# F28x7x_cpu_sys_regs register map
Vendor: Texas Instruments
Peripheral module from a debugger description file (folder C2000).
Address unit: 16 bits
Registers are 32-bit, read-write, no defined reset value unless marked. A register's access mark holds for its fields unless they carry their own. Offsets are as the file gives them; lines under a group give offsets from that group; [hi:lo] are bit positions; {n}, {i} and the like mark numbered series; 'fields as' and 'values as' point back to an identical list; <NAME> marks a mode.

## CPU_SYS_REGS
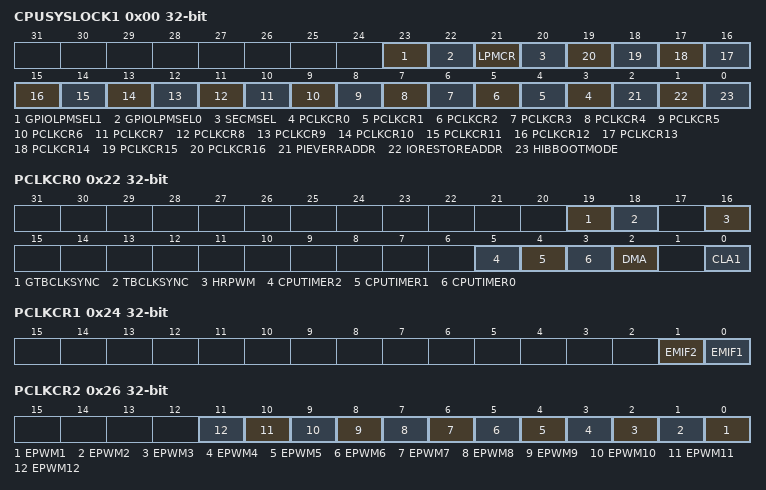
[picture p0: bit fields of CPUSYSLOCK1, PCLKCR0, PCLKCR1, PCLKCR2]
0x00 CPUSYSLOCK1 — Lock bit for CPUSYS registers
  [23] GPIOLPMSEL1 — Lock bit for GPIOLPMSEL1 Register
  [22] GPIOLPMSEL0 — Lock bit for GPIOLPMSEL0 Register
  [21] LPMCR — Lock bit for LPMCR Register
  [20] SECMSEL — Lock bit for SECMSEL Register
  [n+3] PCLKCR{n} (n=0..16) — Lock bit for PCLKCR{n} Register
  [2] PIEVERRADDR — Lock bit for PIEVERRADDR Register
  [1] IORESTOREADDR — Lock bit for IORESTOREADDR Register
  [0] HIBBOOTMODE — Lock bit for HIBBOOTMODE register
0x06 HIBBOOTMODE
  [31:0] BMODE — HIB Boot Mode
0x08 IORESTOREADDR — IORestore() routine Address Register
  [21:0] ADDR — restoreIO() routine address
0x0A PIEVERRADDR — PIE Vector Fetch Error Address register
  [21:0] ADDR — PIE Vector Fetch Error Handler Routine Address
0x22 PCLKCR0 — Peripheral Clock Gating Registers
  [19] GTBCLKSYNC — EPWM Time Base Clock Global sync
  [18] TBCLKSYNC — EPWM Time Base Clock sync
  [16] HRPWM — HRPWM Clock Enable Bit
  [5] CPUTIMER2 — CPUTIMER2 Clock Enable bit
  [4] CPUTIMER1 — CPUTIMER1 Clock Enable bit
  [3] CPUTIMER0 — CPUTIMER0 Clock Enable bit
  [2] DMA — DMA Clock Enable bit
  [0] CLA1 — CLA1 Clock Enable Bit
0x24 PCLKCR1 — Peripheral Clock Gating Registers
  [1] EMIF2 — EMIF2 Clock Enable bit
  [0] EMIF1 — EMIF1 Clock Enable bit
0x26 PCLKCR2 — Peripheral Clock Gating Registers
  [n-1] EPWM{n} (n=1..12) — EPWM{n} Clock Enable bit
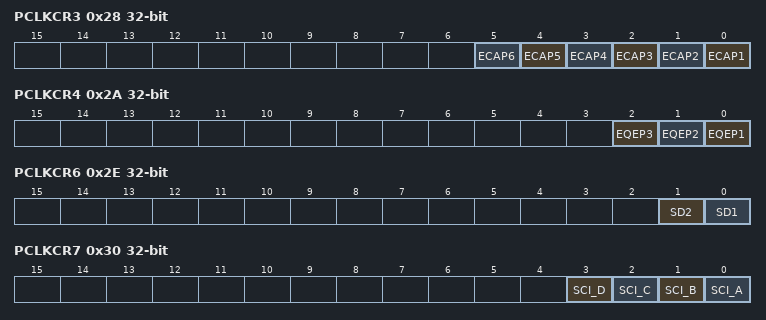
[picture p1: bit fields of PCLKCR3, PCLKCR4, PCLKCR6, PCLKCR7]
0x28 PCLKCR3 — Peripheral Clock Gating Registers
  [n-1] ECAP{n} (n=1..6) — ECAP{n} Clock Enable bit
0x2A PCLKCR4 — Peripheral Clock Gating Registers
  [2] EQEP3 — EQEP3 Clock Enable bit
  [1] EQEP2 — EQEP2 Clock Enable bit
  [0] EQEP1 — EQEP1 Clock Enable bit
0x2C PCLKCR5 access not given — Peripheral Clock Gating Registers
0x2E PCLKCR6 — Peripheral Clock Gating Registers
  [1] SD2 — SD2 Clock Enable bit
  [0] SD1 — SD1 Clock Enable bit
0x30 PCLKCR7 — Peripheral Clock Gating Registers
  [3] SCI_D — SCI_D Clock Enable bit
  [2] SCI_C — SCI_C Clock Enable bit
  [1] SCI_B — SCI_B Clock Enable bit
  [0] SCI_A — SCI_A Clock Enable bit
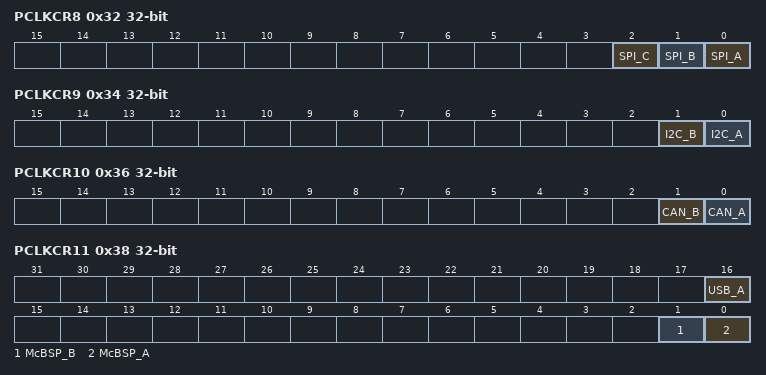
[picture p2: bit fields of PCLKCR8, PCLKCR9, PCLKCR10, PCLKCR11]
0x32 PCLKCR8 — Peripheral Clock Gating Registers
  [2] SPI_C — SPI_C Clock Enable bit
  [1] SPI_B — SPI_B Clock Enable bit
  [0] SPI_A — SPI_A Clock Enable bit
0x34 PCLKCR9 — Peripheral Clock Gating Registers
  [1] I2C_B — I2C_B Clock Enable bit
  [0] I2C_A — I2C_A Clock Enable bit
0x36 PCLKCR10 — Peripheral Clock Gating Registers
  [1] CAN_B — CAN_B Clock Enable bit
  [0] CAN_A — CAN_A Clock Enable bit
0x38 PCLKCR11 — Peripheral Clock Gating Registers
  [16] USB_A — USB_A Clock Enable bit
  [1] McBSP_B — McBSP_B Clock Enable bit
  [0] McBSP_A — McBSP_A Clock Enable bit
0x3A PCLKCR12 — Peripheral Clock Gating Registers
  [0] uPP_A — uPP_A Clock Enable bit
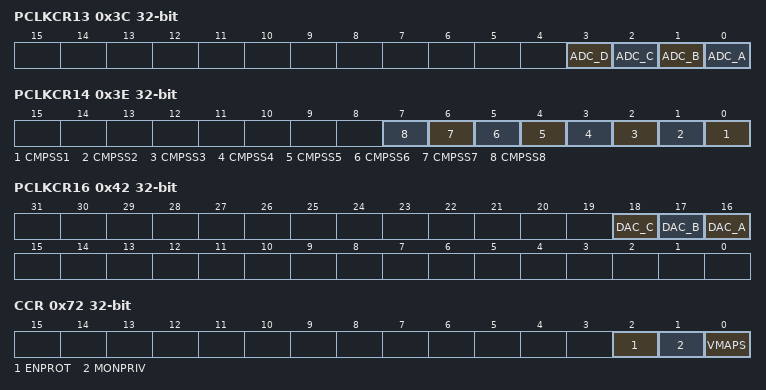
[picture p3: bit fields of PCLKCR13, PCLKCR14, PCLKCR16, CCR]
0x3C PCLKCR13 — Peripheral Clock Gating Registers
  [3] ADC_D — ADC_D Clock Enable bit
  [2] ADC_C — ADC_C Clock Enable bit
  [1] ADC_B — ADC_B Clock Enable bit
  [0] ADC_A — ADC_A Clock Enable bit
0x3E PCLKCR14 — Peripheral Clock Gating Registers
  [n-1] CMPSS{n} (n=1..8) — CMPSS{n} Clock Enable bit
0x42 PCLKCR16 — Peripheral Clock Gating Registers
  [18] DAC_C — Buffered_DAC_C Clock Enable Bit
  [17] DAC_B — Buffered_DAC_B Clock Enable Bit
  [16] DAC_A — Buffered_DAC_A Clock Enable Bit
0x72 CCR — Core Control register (t documented for users)
  [2] ENPROT — C28x ENPROT input signal value
  [1] MONPRIV — C28x MONPRIV input signal enable bit
  [0] VMAPS — C28x cores VMAPS signal status
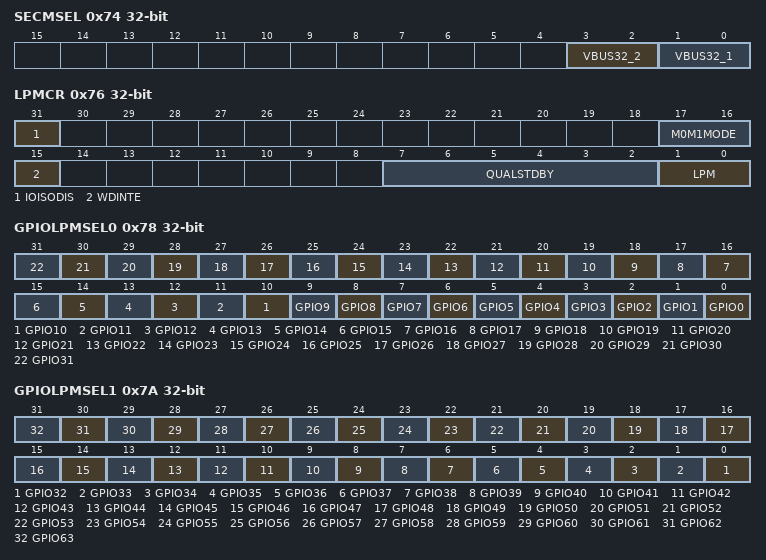
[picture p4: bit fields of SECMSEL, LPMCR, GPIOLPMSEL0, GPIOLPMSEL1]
0x74 SECMSEL — Secondary Master Select register for common peripherals: Selects between CLA & DMA
  [3:2] VBUS32_2 — Secondary Master Select for VBUS32_2 Bridge
  [1:0] VBUS32_1 — Secondary Master Select for VBUS32_1 Bridge
0x76 LPMCR — LPM Control Register
  [31] IOISODIS — IO Isolation Disable
  [17:16] M0M1MODE — Configuration for M0 and M1 mode during HIB
  [15] WDINTE — Enable for WDINT wakeup from STANDBY
  [7:2] QUALSTDBY — STANDBY Wakeup Pin Qualification Setting
  [1:0] LPM — Low Power Mode setting
0x78 GPIOLPMSEL0 — GPIO LPM Wakeup select registers
  [n] GPIO{n} (n=0..31) — GPIO{n} Enable for LPM Wakeup
0x7A GPIOLPMSEL1 — GPIO LPM Wakeup select registers
  [n-32] GPIO{n} (n=32..63) — GPIO{n} Enable for LPM Wakeup
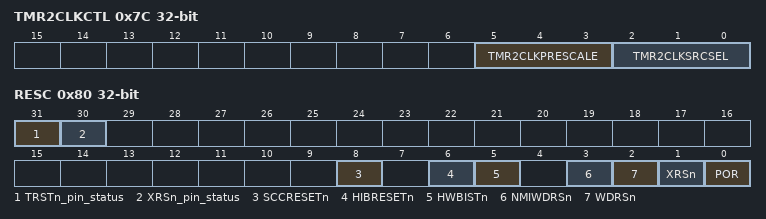
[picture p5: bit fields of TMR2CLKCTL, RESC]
0x7C TMR2CLKCTL — Timer2 Clock Measurement functionality control register
  [5:3] TMR2CLKPRESCALE — CPU Timer 2 Clock Pre-Scale Value
  [2:0] TMR2CLKSRCSEL — CPU Timer 2 Clock Source Select Bit
0x80 RESC — Reset Cause register
  [31] TRSTn_pin_status — TRSTn Status
  [30] XRSn_pin_status
  [8] SCCRESETn — SCCRESETn Reset Cause Indication Bit
  [6] HIBRESETn — HIBRESETn Reset Cause Indication Bit
  [5] HWBISTn — HWBISTn Reset Cause Indication Bit
  [3] NMIWDRSn — NMIWDRSn Reset Cause Indication Bit
  [2] WDRSn — WDRSn Reset Cause Indication Bit
  [1] XRSn — XRSn Reset Cause Indication Bit
  [0] POR — POR Reset Cause Indication Bit
